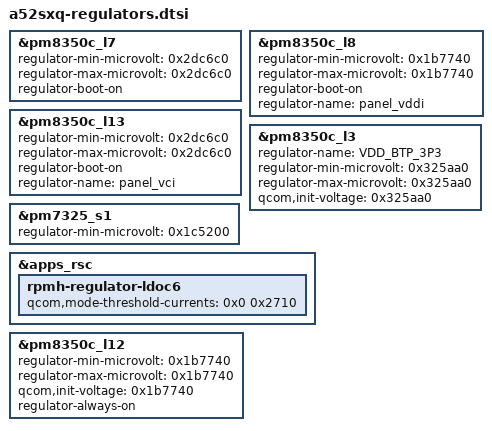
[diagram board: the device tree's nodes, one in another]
// SPDX-License-Identifier: GPL-2.0
/*
 * a52sxq board description for the Qualcomm 6.12 yupik base: regulators
 * GENERATED by tools/gen.py from the phone's stock dtbo (5.4 bindings, values verbatim).
 * Do not edit: hand-written 6.12 changes live in a52sxq-bsp612-fixups.dtsi.
 */

&pm8350c_l7 {
	regulator-min-microvolt = <0x2dc6c0>;
	regulator-max-microvolt = <0x2dc6c0>;
	regulator-boot-on;
};

&pm8350c_l8 {
	regulator-min-microvolt = <0x1b7740>;
	regulator-max-microvolt = <0x1b7740>;
	regulator-boot-on;
	regulator-name = "panel_vddi";
};

&pm8350c_l13 {
	regulator-min-microvolt = <0x2dc6c0>;
	regulator-max-microvolt = <0x2dc6c0>;
	regulator-boot-on;
	regulator-name = "panel_vci";
};

&pm8350c_l3 {
	regulator-name = "VDD_BTP_3P3";
	regulator-min-microvolt = <0x325aa0>;
	regulator-max-microvolt = <0x325aa0>;
	qcom,init-voltage = <0x325aa0>;
};

&pm7325_s1 {
	regulator-min-microvolt = <0x1c5200>;
};

&apps_rsc {

	rpmh-regulator-ldoc6 {
		qcom,mode-threshold-currents = <0x0 0x2710>;
	};
};

&pm8350c_l12 {
	regulator-min-microvolt = <0x1b7740>;
	regulator-max-microvolt = <0x1b7740>;
	qcom,init-voltage = <0x1b7740>;
	regulator-always-on;
};

